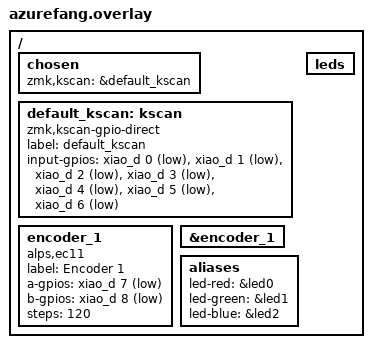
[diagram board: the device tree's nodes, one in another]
#include <dt-bindings/zmk/matrix_transform.h>

/ {
    chosen {
        zmk,kscan = &default_kscan;
    };

    default_kscan: kscan {
        compatible = "zmk,kscan-gpio-direct";
        label = "default_kscan";
        
        input-gpios
        = <&xiao_d 0 (GPIO_ACTIVE_LOW | GPIO_PULL_UP)>
        , <&xiao_d 1 (GPIO_ACTIVE_LOW | GPIO_PULL_UP)>
        , <&xiao_d 2 (GPIO_ACTIVE_LOW | GPIO_PULL_UP)>
        , <&xiao_d 3 (GPIO_ACTIVE_LOW | GPIO_PULL_UP)>
        , <&xiao_d 4 (GPIO_ACTIVE_LOW | GPIO_PULL_UP)>
        , <&xiao_d 5 (GPIO_ACTIVE_LOW | GPIO_PULL_UP)>
        , <&xiao_d 6 (GPIO_ACTIVE_LOW | GPIO_PULL_UP)>
        ;
    };

    encoder_1: encoder_1 {
        compatible = "alps,ec11";
        label = "Encoder 1";
        a-gpios = <&xiao_d 7 (GPIO_ACTIVE_LOW | GPIO_PULL_UP)>;
        b-gpios = <&xiao_d 8 (GPIO_ACTIVE_LOW | GPIO_PULL_UP)>;
        steps = <120>;
    };

    &encoder_1 {
    status = "okay";
    };

    aliases {
        led-red = &led0;
        led-green = &led1;
        led-blue = &led2;
    };

    leds {
        status = "okay";
    };
};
